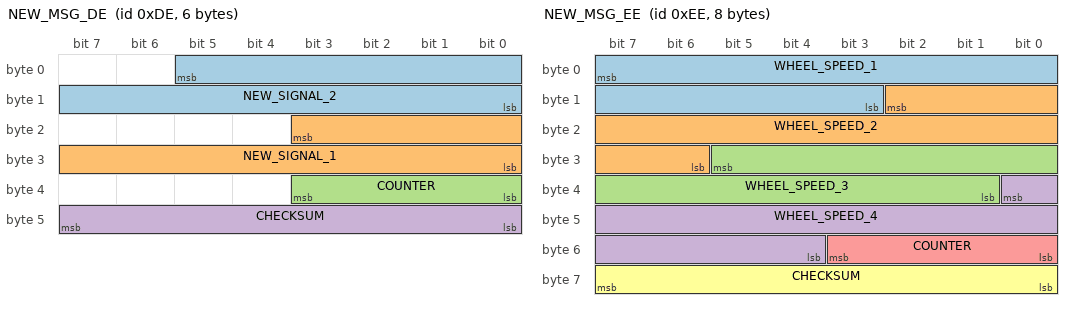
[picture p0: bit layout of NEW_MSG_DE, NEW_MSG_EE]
BO_ 222 NEW_MSG_DE: 6 XXX
 SG_ NEW_SIGNAL_2 : 5|14@0+ (1,0) [0|16383] "" XXX
 SG_ NEW_SIGNAL_1 : 19|12@0+ (1,0) [0|4095] "" XXX
 SG_ COUNTER : 35|4@0+ (1,0) [0|15] "" XXX
 SG_ CHECKSUM : 47|8@0+ (1,0) [0|255] "" XXX

BO_ 238 NEW_MSG_EE: 8 XXX
 SG_ WHEEL_SPEED_1 : 7|13@0+ (1,0) [0|8191] "" XXX
 SG_ WHEEL_SPEED_2 : 10|13@0+ (1,0) [0|8191] "" XXX
 SG_ WHEEL_SPEED_3 : 29|13@0+ (1,0) [0|8191] "" XXX
 SG_ WHEEL_SPEED_4 : 32|13@0+ (1,0) [0|8191] "" XXX
 SG_ COUNTER : 51|4@0+ (1,0) [0|15] "" XXX
 SG_ CHECKSUM : 63|8@0+ (1,0) [0|255] "" XXX

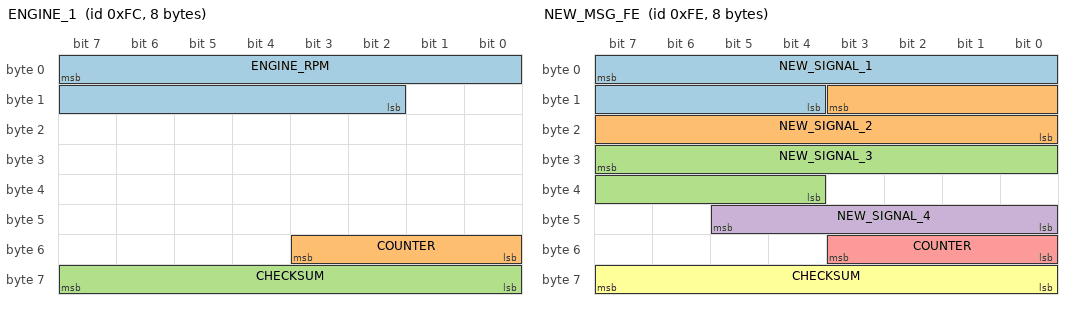
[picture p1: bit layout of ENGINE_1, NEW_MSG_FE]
BO_ 252 ENGINE_1: 8 XXX
 SG_ ENGINE_RPM : 7|14@0+ (1,0) [0|255] "" XXX
 SG_ COUNTER : 51|4@0+ (1,0) [0|15] "" XXX
 SG_ CHECKSUM : 63|8@0+ (1,0) [0|255] "" XXX

BO_ 254 NEW_MSG_FE: 8 XXX
 SG_ NEW_SIGNAL_1 : 7|12@0+ (1,0) [0|4095] "" XXX
 SG_ NEW_SIGNAL_2 : 11|12@0+ (1,0) [0|4095] "" XXX
 SG_ NEW_SIGNAL_3 : 31|12@0+ (1,0) [0|4095] "" XXX
 SG_ NEW_SIGNAL_4 : 45|6@0+ (1,0) [0|63] "" XXX
 SG_ COUNTER : 51|4@0+ (1,0) [0|15] "" XXX
 SG_ CHECKSUM : 63|8@0+ (1,0) [0|255] "" XXX

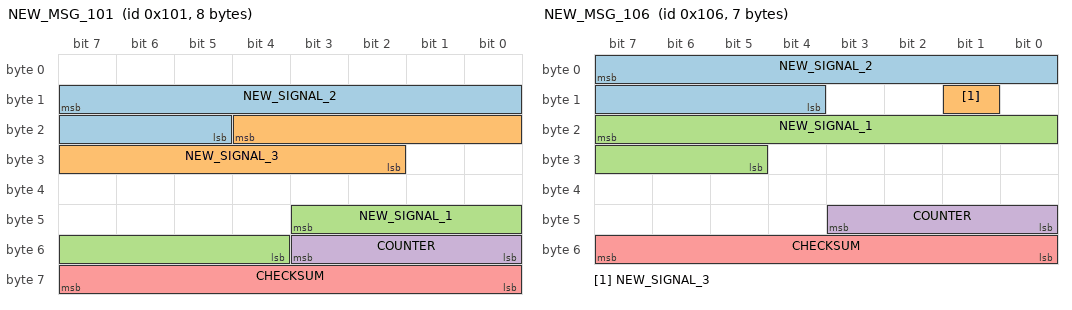
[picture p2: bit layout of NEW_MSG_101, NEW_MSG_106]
BO_ 257 NEW_MSG_101: 8 XXX
 SG_ NEW_SIGNAL_2 : 15|11@0+ (1,0) [0|2047] "" XXX
 SG_ NEW_SIGNAL_3 : 20|11@0+ (1,0) [0|2047] "" XXX
 SG_ NEW_SIGNAL_1 : 43|8@0+ (1,0) [0|255] "" XXX
 SG_ COUNTER : 51|4@0+ (1,0) [0|15] "" XXX
 SG_ CHECKSUM : 63|8@0+ (1,0) [0|255] "" XXX

BO_ 262 NEW_MSG_106: 7 XXX
 SG_ NEW_SIGNAL_2 : 7|12@0+ (1,0) [0|4095] "" XXX
 SG_ NEW_SIGNAL_3 : 9|1@0+ (1,0) [0|1] "" XXX
 SG_ NEW_SIGNAL_1 : 23|11@0+ (1,0) [0|2047] "" XXX
 SG_ COUNTER : 43|4@0+ (1,0) [0|15] "" XXX
 SG_ CHECKSUM : 55|8@0+ (1,0) [0|255] "" XXX

BO_ 263 NEW_MSG_107: 8 XXX
 SG_ NEW_SIGNAL_1 : 7|8@0+ (1,0) [0|255] "" XXX

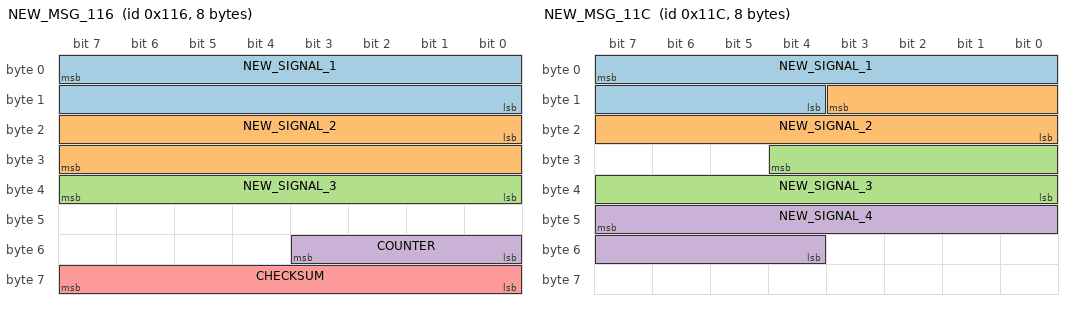
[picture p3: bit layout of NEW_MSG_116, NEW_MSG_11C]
BO_ 278 NEW_MSG_116: 8 XXX
 SG_ NEW_SIGNAL_1 : 7|16@0+ (1,0) [0|65535] "" XXX
 SG_ NEW_SIGNAL_2 : 16|16@1+ (1,0) [0|65535] "" XXX
 SG_ NEW_SIGNAL_3 : 39|8@0+ (1,0) [0|255] "" XXX
 SG_ COUNTER : 51|4@0+ (1,0) [0|15] "" XXX
 SG_ CHECKSUM : 63|8@0+ (1,0) [0|255] "" XXX

BO_ 284 NEW_MSG_11C: 8 XXX
 SG_ NEW_SIGNAL_1 : 7|12@0+ (1,0) [0|4095] "" XXX
 SG_ NEW_SIGNAL_2 : 11|12@0+ (1,0) [0|4095] "" XXX
 SG_ NEW_SIGNAL_3 : 28|13@0+ (1,0) [0|8191] "" XXX
 SG_ NEW_SIGNAL_4 : 47|12@0+ (1,0) [0|4095] "" XXX

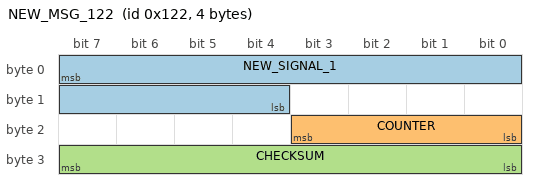
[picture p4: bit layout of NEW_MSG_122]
BO_ 290 NEW_MSG_122: 4 XXX
 SG_ NEW_SIGNAL_1 : 7|12@0+ (1,0) [0|4095] "" XXX
 SG_ COUNTER : 19|4@0+ (1,0) [0|15] "" XXX
 SG_ CHECKSUM : 31|8@0+ (1,0) [0|255] "" XXX

BO_ 762 NEW_MSG_2FA: 3 XXX
 SG_ NEW_SIGNAL_1 : 7|8@0+ (1,0) [0|255] "" XXX
